# PIC32CM3204PL10020 register map
Vendor: Microchip Technology; Series: PIC32CMPL10; File version: 0
CPU: CM0+ r0p0, little endian, no MPU, no FPU, VTOR, 2 interrupt priority bits, 15 interrupts
Registers are 32-bit, read-write, reset 0x0 unless marked. A register's access mark holds for its fields unless they carry their own. Offsets are from the block's base; [hi:lo] are bit positions; {n}, {i} and the like mark numbered series; 'fields as' and 'values as' point back to an identical list.

## CCL — Configurable Custom Logic
Base 0x42002400
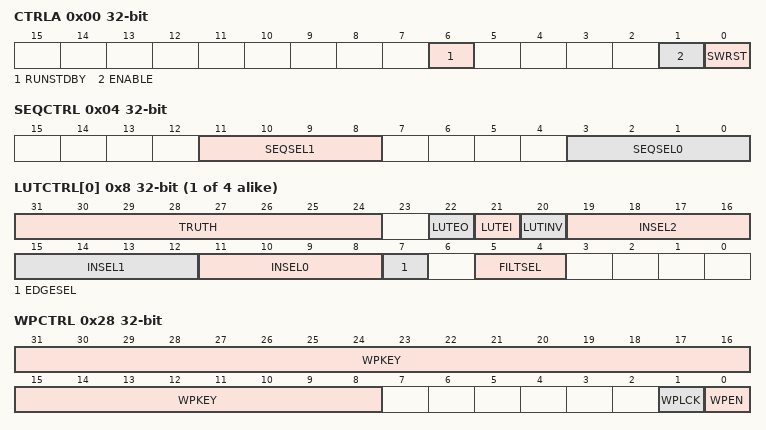
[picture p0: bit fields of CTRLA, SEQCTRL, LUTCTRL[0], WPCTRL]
0x00 CTRLA — Control A
  [6] RUNSTDBY — Run in Standby
  [1] ENABLE
  [0] SWRST — Software Reset
0x04 SEQCTRL — Sequential Control
  [11:8] SEQSEL1 — Sequential Selection 1
    0=DISABLE (Sequential logic is disabled); 1=DFF (D flip-flop); 2=JK (JK flip-flop); 3=LATCH (D latch); 4=RS (RS latch)
  [3:0] SEQSEL0 — Sequential Selection 0
    values as SEQSEL1
{0x8+4i} LUTCTRL[{i}] (i=0..3) — LUT Control #
  [31:24] TRUTH — Truth Table
  [22] LUTEO — LUT Event Output Enable
  [21] LUTEI — LUT Event Input Enable
  [20] LUTINV — LUT Inverted Event Input Enable
  [19:16] INSEL2 — LUT Input 2 Source Selection
    0=MASK (Masked input); 1=FEEDBACK (Feedback input source); 2=LINK (Linked LUT input source); 3=EVENT (Event input source); 4=IO (I/O pin input source); 5=AC (AC input source: CMP[0] (LUT0) / CMP[1] (LUT1) / CMP[0] (LUT2) / CMP[1] (LUT3)); 6=TC (TC input source: TC0 (LUT0) / TC1 (LUT1) / TC2 (LUT2) / TC0 (LUT3)); 8=TCC (TCC input source: TCC0); 9=SERCOM (SERCOM input source: SERCOM0 (LUT0) / SERCOM1 (LUT1) / SERCOM0 (LUT2) / SERCOM1 (LUT3)); 11=ASYNCEVENT (Asynchronous event input source)
  [15:12] INSEL1 — LUT Input 1 Source Selection
    values as INSEL2
  [11:8] INSEL0 — LUT Input 0 Source Selection
    values as INSEL2
  [7] EDGESEL — Edge Selection
  [5:4] FILTSEL — Filter Selection
    0=DISABLE (Filter disabled); 1=SYNCH (Synchronizer enabled); 2=FILTER (Filter enabled)
0x28 WPCTRL — Write Protection Control
  [31:8] WPKEY — Write Protection Key
    0x43434C=KEY (Allow writes to the WPCTRL register)
  [1] WPLCK — Write Protection Lock
  [0] WPEN — Write Protection Enable

## DSU — Device Service Unit
Base 0x41002000
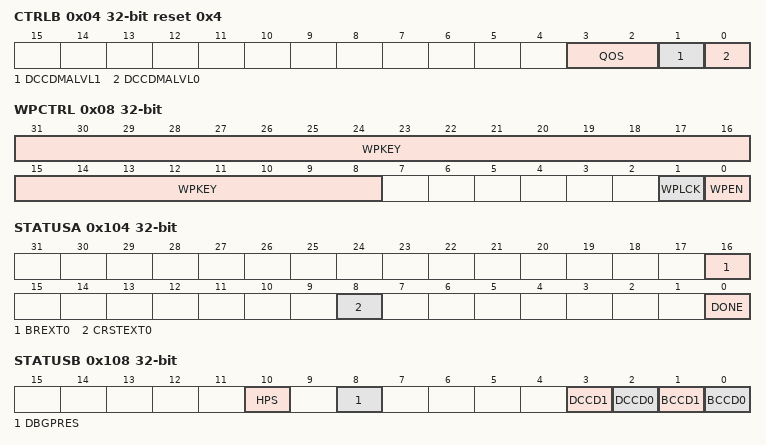
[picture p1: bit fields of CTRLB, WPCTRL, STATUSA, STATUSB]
0x04 CTRLB reset 0x4 — Control B
  [3:2] QOS — DSU QoS Level
    0=DISABLE (Background (no sensitive operation)); 1=LOW (Sensitive bandwidth); 2=MEDIUM (Sensitive latency); 3=HIGH (Critical latency)
  [1] DCCDMALVL1 — DMA Trigger 1 Level
    0=EMPTY (Trigger n rises when DCCn is read and falls when it is written); 1=FULL (Trigger n rises when DCCn is written and falls when it is read)
  [0] DCCDMALVL0 — DMA Trigger 0 Level
    values as DCCDMALVL1
0x08 WPCTRL — Write Protection Control
  [31:8] WPKEY — Write Protection Key
    0x445355=KEY (Allow writes to the WPCTRL register)
  [1] WPLCK — Write Protection Lock
  [0] WPEN — Write Protection Enable
0x100 CTRLC — Control C
  [0] DBGRW0 — CPU0 Debug R/W
0x104 STATUSA ro
  [16] BREXT0 — Boot ROM 0 Phase Extension Status
  [8] CRSTEXT0 — CPU0 Reset Extension Status
  [0] DONE — Done Status
0x108 STATUSB ro
  [10] HPS — Hot-plugging Status
  [8] DBGPRES — Debugger Present Status
  [3] DCCD1 — Debug Communication Channel 1 Dirty
  [2] DCCD0 — Debug Communication Channel 0 Dirty
  [1] BCCD1 — Boot ROM Communication Channel 1 Dirty
  [0] BCCD0 — Boot ROM Communication Channel 0 Dirty
{0x110+4i} BCC[{i}] (i=0..1) — Boot ROM Channel #
  [31:0] DATA
{0x118+4i} DCC[{i}] (i=0..1) — Debug Communication Channel #
  [31:0] DATA
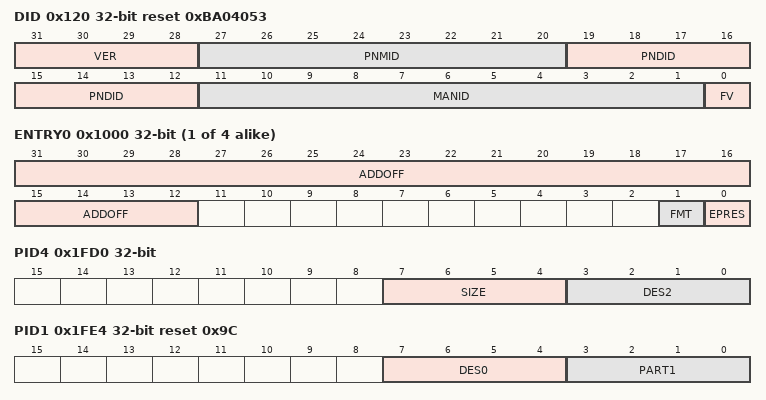
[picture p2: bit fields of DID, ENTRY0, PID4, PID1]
0x120 DID ro reset 0xBA04053 — Device Identification
  [31:28] VER — Version Code
  [27:20] PNMID — Part Number Mask ID
  [19:12] PNDID — Part Number Device ID
  [11:1] MANID — JEDEC Manufacture ID
  [0] FV — Fixed Value of 1
0x124 DAL ro — Debugger Access Level
  [1:0] CPU0 — CPU 0 Debugger Access Level
    0=SECURED (The Debugger targeting the CPU0 domain can only access the DSU external address space; otherwise, debugger access is disabled.); 2=FULL_DEBUG (The Debugger has unrestricted access)
{0x1000+4i} ENTRY{i} ro (i=0..3) — CoreSight ROM Table Entry {i}
  [31:12] ADDOFF — CoreSight ROM Table Address Offset
  [1] FMT — CoreSight Rom Table Format
  [0] EPRES — CoreSight Entry Present
0x1FCC MEMTYPE ro — CoreSight ROM Table Memory Type
  [0] SYSMEM — CoreSight System Memory Present
0x1FD0 PID4 ro — CoreSight Peripheral Identification 4
  [7:4] SIZE — CoreSight Size
  [3:0] DES2 — CoreSight JEP-106 Continuation Code
{0x1FC0+4i} PID{i} ro (i=5..7) — CoreSight Peripheral Identification {i}
  [7:0] RES0 — CoreSight Reserved Field
0x1FE0 PID0 ro reset 0xD0 — CoreSight Peripheral Identification 0
  [7:0] PART0 — CoreSight Part Number Bits
0x1FE4 PID1 ro reset 0x9C — CoreSight Peripheral Identification 1
  [7:4] DES0 — CoreSight JEP106 Identification Code Bits
  [3:0] PART1 — CoreSight Part Number Bits
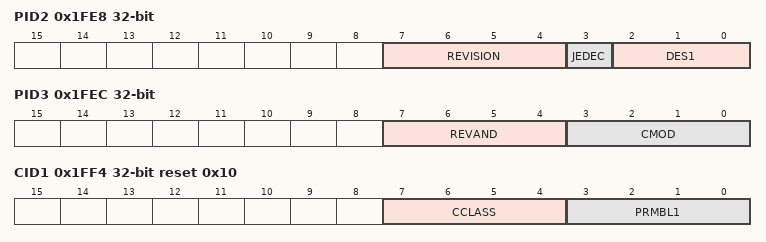
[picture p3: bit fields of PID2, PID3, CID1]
0x1FE8 PID2 ro — CoreSight Peripheral Identification 2
  [7:4] REVISION — CoreSight Revision Number
  [3] JEDEC — CoreSight JEDEC Assignment
  [2:0] DES1 — CoreSight JEP106 Identification Code Bits
0x1FEC PID3 ro — CoreSight Peripheral Identification 3
  [7:4] REVAND — CoreSight REVAND
  [3:0] CMOD — CoreSight Custom Modifier 0
0x1FF0 CID0 ro reset 0xD — CoreSight Component Identification 0
  [7:0] PRMBL0 — CoreSight Preamble 0
0x1FF4 CID1 ro reset 0x10 — CoreSight Component Identification 1
  [7:4] CCLASS — CoreSight Component Class
  [3:0] PRMBL1 — CoreSight Preamble 1
0x1FF8 CID2 ro reset 0x5 — CoreSight Component Identification 2
  [7:0] PRMBL2 — CoreSight Preamble 2
0x1FFC CID3 ro reset 0xB1 — CoreSight Component Identification 3
  [7:0] PRMBL3 — CoreSight Preamble 3
